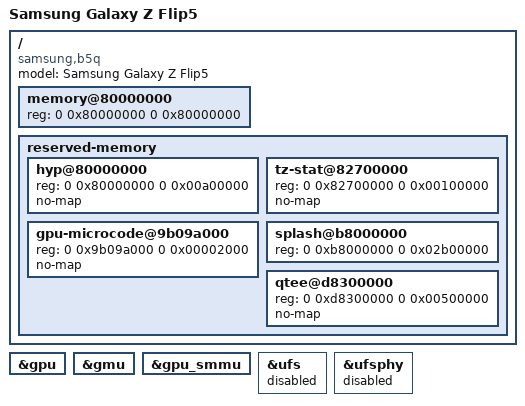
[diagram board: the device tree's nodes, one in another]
// SPDX-License-Identifier: BSD-3-Clause
// XNU hardware description, not a bootloader FDT replacement.
// Evidence: reports/official-firmware-hardware.json (F7310ZCS7EYF3).
/dts-v1/;
/include/ "sm8550.dtsi"

/ {
    model = "Samsung Galaxy Z Flip5";
    compatible = "samsung,b5q", "qcom,sm8550";

    // SM8550/b5q low physical DRAM bank, from b5q reference /ddr-regions/region0.
    // Supplies nonzero chosen/dram-base/size and classifies 0xB8000000
    // framebuffer memory as DRAM. This is not the full allocatable RAM map
    // and does not replace calibration against the live firmware FDT.
    // DarwinBoot still allocates the XNU-owned window from the EFI map.
    memory@80000000 {
        device_type = "memory";
        reg = <0 0x80000000 0 0x80000000>;
    };
    reserved-memory {
        #address-cells = <2>;
        #size-cells = <2>;
        ranges;
        hyp@80000000 {
            reg = <0 0x80000000 0 0x00a00000>;
            no-map;
        };
        tz-stat@82700000 {
            reg = <0 0x82700000 0 0x00100000>;
            no-map;
        };
        gpu-microcode@9b09a000 {
            reg = <0 0x9b09a000 0 0x00002000>;
            no-map;
        };
        splash@b8000000 {
            reg = <0 0xb8000000 0 0x02b00000>;
            // This is a reservation, not an active framebuffer node.
            // Stock splash is mappable; preserve its lack of no-map.
        };
        qtee@d8300000 {
            reg = <0 0xd8300000 0 0x00500000>;
            no-map;
        };
    };
};

// The rest of the live reservation set (including UH/RKP) must be enforced
// by b5q firmware from its incoming FDT/EFI map. This subset never defines
// the extent of allocatable RAM.
// Keep the hardware FDT nodes enabled. The current ADT converter does not
// export the AAPL,phandle needed by IOKit to resolve GPU and GMU interrupts.
&gpu { status = "okay"; };
&gmu { status = "okay"; };
&gpu_smmu { status = "okay"; };
// Root transport warm-adopts exact stock-DT MMIO directly in B5qUfs;
// leave generic DT-matched UFS/PHY drivers disabled to prevent a second owner.
&ufs { status = "disabled"; };
&ufsphy { status = "disabled"; };
